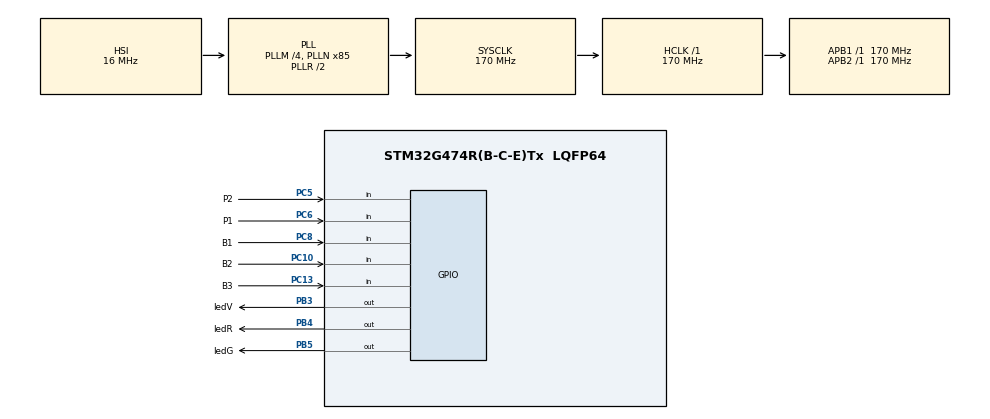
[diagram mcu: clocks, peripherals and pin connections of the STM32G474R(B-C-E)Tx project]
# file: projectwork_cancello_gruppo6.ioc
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Mcu.Family=STM32G4
Mcu.Name=STM32G474R(B-C-E)Tx
Mcu.Package=LQFP64
NVIC.PriorityGroup=NVIC_PRIORITYGROUP_4
PB3.GPIO_Label=ledV
PB3.Signal=GPIO_Output
PB4.GPIO_Label=ledR
PB4.Signal=GPIO_Output
PB5.GPIO_Label=ledG
PB5.Signal=GPIO_Output
PC10.GPIO_Label=B2
PC10.GPIO_PuPd=GPIO_PULLDOWN
PC10.Signal=GPIO_Input
PC13.GPIO_Label=B3
PC13.GPIO_PuPd=GPIO_PULLDOWN
PC13.Signal=GPIO_Input
PC5.GPIO_Label=P2
PC5.GPIO_PuPd=GPIO_PULLDOWN
PC5.Signal=GPIO_Input
PC6.GPIO_Label=P1
PC6.GPIO_PuPd=GPIO_PULLDOWN
PC6.Signal=GPIO_Input
PC8.GPIO_Label=B1
PC8.GPIO_PuPd=GPIO_PULLDOWN
PC8.Signal=GPIO_Input
ProjectManager.HeapSize=0x200
ProjectManager.StackSize=0x400
ProjectManager.TargetToolchain=STM32CubeIDE
RCC.ADC12Freq_Value=170000000
RCC.ADC345Freq_Value=170000000
RCC.AHBFreq_Value=170000000
RCC.APB1Freq_Value=170000000
RCC.APB1TimFreq_Value=170000000
RCC.APB2Freq_Value=170000000
RCC.APB2TimFreq_Value=170000000
RCC.CortexFreq_Value=170000000
RCC.EXTERNAL_CLOCK_VALUE=12288000
RCC.HCLKFreq_Value=170000000
RCC.HSE_VALUE=24000000
RCC.HSI48_VALUE=48000000
RCC.HSI_VALUE=16000000
RCC.LSE_VALUE=32768
RCC.PLLM=RCC_PLLM_DIV4
RCC.PLLN=85
RCC.RTCClockSelection=RCC_RTCCLKSOURCE_LSE
RCC.SYSCLKFreq_VALUE=170000000
RCC.SYSCLKSource=RCC_SYSCLKSOURCE_PLLCLK
RCC.USBFreq_Value=170000000
RCC.VCOOutputFreq_Value=340000000
VP_SYS_VS_DBSignals.Mode=DisableDeadBatterySignals
board=NUCLEO-G474RE

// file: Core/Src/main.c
/* USER CODE BEGIN Header */
/**
 ******************************************************************************
 * @file           : main.c
 * @brief          : Main program body
 ******************************************************************************
 * @attention
 *
 * Copyright (c) 2024 STMicroelectronics.
 * All rights reserved.
 *
 * This software is licensed under terms that can be found in the LICENSE file
 * in the root directory of this software component.
 * If no LICENSE file comes with this software, it is provided AS-IS.
 *
 ******************************************************************************
 */
/* USER CODE END Header */
#include "main.h"
#include "gpio.h"

/* USER CODE BEGIN Includes */
#include "project_work_cancello.h"
/* USER CODE END Includes */

void SystemClock_Config(void);

/* USER CODE BEGIN 0 */
static void FSM_A_read_inputs() {
	rtU.P1 = !HAL_GPIO_ReadPin(GPIOC, GPIO_PIN_6);
	rtU.P2 = !HAL_GPIO_ReadPin(GPIOC, GPIO_PIN_5);
	rtU.In3 = !HAL_GPIO_ReadPin(GPIOC, GPIO_PIN_8);
	rtU.In4 = !HAL_GPIO_ReadPin(GPIOC, GPIO_PIN_13);
	rtU.In5 = !HAL_GPIO_ReadPin(GPIOC, GPIO_PIN_10);
}

static void FSM_A_write_outputs() {
	HAL_GPIO_WritePin(GPIOB, GPIO_PIN_5, rtY.Out3);
	HAL_GPIO_WritePin(GPIOB, GPIO_PIN_3, rtY.out);
	HAL_GPIO_WritePin(GPIOB, GPIO_PIN_4, rtY.L1);
}
/* USER CODE END 0 */

int main(void)
{

  /* MCU Configuration--------------------------------------------------------*/

  /* Reset of all peripherals, Initializes the Flash interface and the Systick. */
  HAL_Init();

  /* Configure the system clock */
  SystemClock_Config();

  /* Initialize all configured peripherals */
  MX_GPIO_Init();
  /* USER CODE BEGIN 2 */
  project_work_cancello_initialize();
  /* USER CODE END 2 */

  /* Infinite loop */
	while (1) {

				uint32_t start, elapsed;
				start = HAL_GetTick();

				FSM_A_read_inputs();
				project_work_cancello_step();
				FSM_A_write_outputs();

				elapsed = HAL_GetTick() - start;
				HAL_Delay(100 - elapsed);
	}
}

void SystemClock_Config(void)
{
  RCC_OscInitTypeDef RCC_OscInitStruct = {0};
  RCC_ClkInitTypeDef RCC_ClkInitStruct = {0};

  /** Configure the main internal regulator output voltage
  */
  HAL_PWREx_ControlVoltageScaling(PWR_REGULATOR_VOLTAGE_SCALE1_BOOST);

  /** Initializes the RCC Oscillators according to the specified parameters
  * in the RCC_OscInitTypeDef structure.
  */
  RCC_OscInitStruct.OscillatorType = RCC_OSCILLATORTYPE_HSI;
  RCC_OscInitStruct.HSIState = RCC_HSI_ON;
  RCC_OscInitStruct.HSICalibrationValue = RCC_HSICALIBRATION_DEFAULT;
  RCC_OscInitStruct.PLL.PLLState = RCC_PLL_ON;
  RCC_OscInitStruct.PLL.PLLSource = RCC_PLLSOURCE_HSI;
  RCC_OscInitStruct.PLL.PLLM = RCC_PLLM_DIV4;
  RCC_OscInitStruct.PLL.PLLN = 85;
  RCC_OscInitStruct.PLL.PLLP = RCC_PLLP_DIV2;
  RCC_OscInitStruct.PLL.PLLQ = RCC_PLLQ_DIV2;
  RCC_OscInitStruct.PLL.PLLR = RCC_PLLR_DIV2;
  if (HAL_RCC_OscConfig(&RCC_OscInitStruct) != HAL_OK)
  {
    Error_Handler();
  }

  /** Initializes the CPU, AHB and APB buses clocks
  */
  RCC_ClkInitStruct.ClockType = RCC_CLOCKTYPE_HCLK|RCC_CLOCKTYPE_SYSCLK
                              |RCC_CLOCKTYPE_PCLK1|RCC_CLOCKTYPE_PCLK2;
  RCC_ClkInitStruct.SYSCLKSource = RCC_SYSCLKSOURCE_PLLCLK;
  RCC_ClkInitStruct.AHBCLKDivider = RCC_SYSCLK_DIV1;
  RCC_ClkInitStruct.APB1CLKDivider = RCC_HCLK_DIV1;
  RCC_ClkInitStruct.APB2CLKDivider = RCC_HCLK_DIV1;

  if (HAL_RCC_ClockConfig(&RCC_ClkInitStruct, FLASH_LATENCY_4) != HAL_OK)
  {
    Error_Handler();
  }
}

void Error_Handler(void)
{
	__disable_irq();
	while (1) {
	}
}
